# MCU_NAVSS0_PROXY_CFG_GCFG register map
Vendor: Texas Instruments
Peripheral module from a debugger description file (folder J7VCL).
Registers are 32-bit, read-only, reset 0x66340100 unless marked. A register's access mark holds for its fields unless they carry their own. Offsets are as the file gives them; lines under a group give offsets from that group; [hi:lo] are bit positions; {n}, {i} and the like mark numbered series; 'fields as' and 'values as' point back to an identical list; <NAME> marks a mode.

## MCU_NAVSS0_PROXY_CFG_GCFG
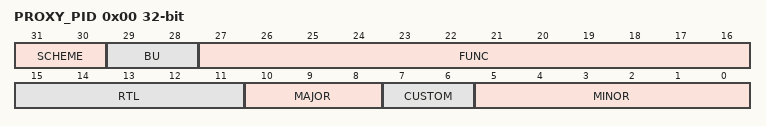
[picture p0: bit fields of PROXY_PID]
0x00 PROXY_PID (reset mask 0xFFFF07FF) — The Revision Register contains the major and minor revisions for the module. Reset = 66349100h
  [31:30] SCHEME — PID register scheme
  [29:28] BU
  [27:16] FUNC — Module ID
  [15:11] RTL — RTL revision.12h in this device.
  [10:8] MAJOR — Major revision
  [7:6] CUSTOM
  [5:0] MINOR — Minor revision
0x04 PROXY_CONFIG reset 0x40 — The Config Register shows configured params.
  [15:0] THREADS — Number of proxy threads supported.
0x14 PROXY_GLB_EVT access per field reset 0xFFFF — The Global Event Register defines the event to send for a global error.
  [15:0] ERR_EVENT rw — Global error event destination. 0xFFFF disables the event
